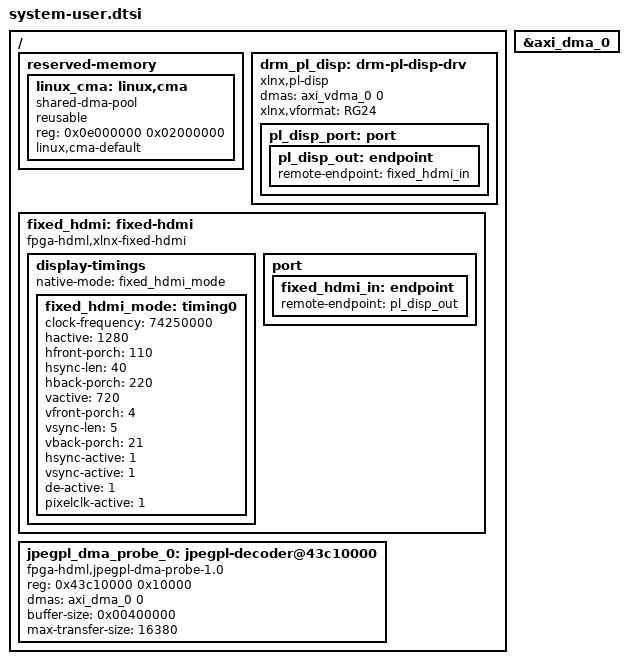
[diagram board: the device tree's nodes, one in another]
/include/ "system-conf.dtsi"

/ {
	reserved-memory {
		#address-cells = <1>;
		#size-cells = <1>;
		ranges;

		linux_cma: linux,cma {
			compatible = "shared-dma-pool";
			reusable;
			reg = <0x0e000000 0x02000000>;
			linux,cma-default;
		};
	};

	drm_pl_disp: drm-pl-disp-drv {
		compatible = "xlnx,pl-disp";
		dmas = <&axi_vdma_0 0>;
		dma-names = "dma0";
		xlnx,vformat = "RG24";

		pl_disp_port: port {
			pl_disp_out: endpoint {
				remote-endpoint = <&fixed_hdmi_in>;
			};
		};
	};

	fixed_hdmi: fixed-hdmi {
		compatible = "fpga-hdml,xlnx-fixed-hdmi";

		display-timings {
			native-mode = <&fixed_hdmi_mode>;

			fixed_hdmi_mode: timing0 {
				clock-frequency = <74250000>;
				hactive = <1280>;
				hfront-porch = <110>;
				hsync-len = <40>;
				hback-porch = <220>;
				vactive = <720>;
				vfront-porch = <4>;
				vsync-len = <5>;
				vback-porch = <21>;
				hsync-active = <1>;
				vsync-active = <1>;
				de-active = <1>;
				pixelclk-active = <1>;
			};
		};

		port {
			fixed_hdmi_in: endpoint {
				remote-endpoint = <&pl_disp_out>;
			};
		};
	};
};

&axi_dma_0 {
	status = "okay";
};

/ {
	jpegpl_dma_probe_0: jpegpl-decoder@43c10000 {
		compatible = "fpga-hdml,jpegpl-dma-probe-1.0";
		reg = <0x43c10000 0x10000>;
		dmas = <&axi_dma_0 0>;
		dma-names = "tx";
		buffer-size = <0x00400000>;
		max-transfer-size = <16380>;
	};
};
